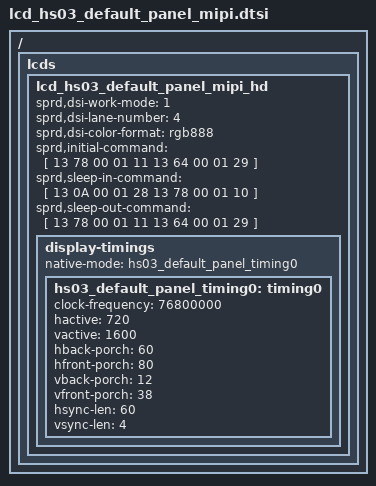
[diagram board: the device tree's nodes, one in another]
/**
*Name：<lcd_hs03_default_panel_mipi>
*Author：<huangzhongjie>
*Date：<2021/10/15>
*Purpose：<HS03 default screen LCD driver>
*/
/ {
    fragment {
        target-path = "/";
        __overlay__ {
            lcds {
                lcd_hs03_default_panel_mipi_hd: lcd_hs03_default_panel_mipi_hd {

                    sprd,dsi-work-mode = <1>; /* video burst mode*/
                    sprd,dsi-lane-number = <4>;
                    sprd,dsi-color-format = "rgb888";

                    sprd,initial-command = [
                        13 78 00 01 11
                        13 64 00 01 29
                        ];
                    sprd,sleep-in-command = [
                        13 0A 00 01 28
                        13 78 00 01 10
                        ];
                    sprd,sleep-out-command = [
                        13 78 00 01 11
                        13 64 00 01 29
                        ];

                    display-timings {
                        native-mode = <&hs03_default_panel_timing0>;

                        hs03_default_panel_timing0: timing0 {
                            clock-frequency = <76800000>;
                            hactive = <720>;
                            vactive = <1600>;
                            hback-porch = <60>;
                            hfront-porch = <80>;
                            vback-porch = <12>;
                            vfront-porch = <38>;
                            hsync-len = <60>;
                            vsync-len = <4>;
                        };
                    };
                };
            };
        };
    };
};
